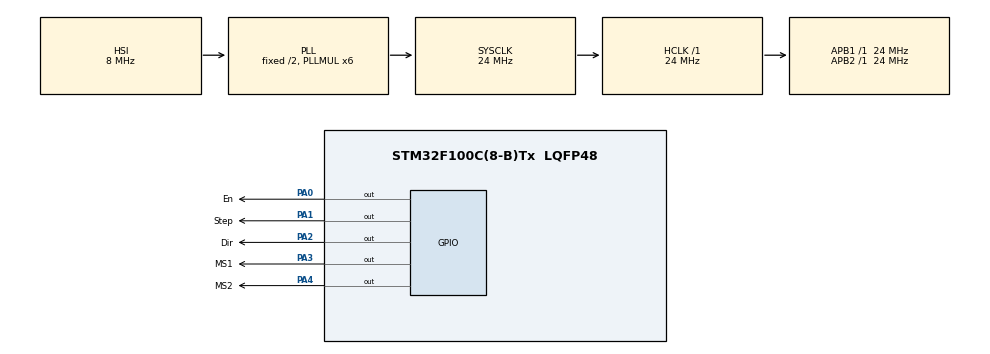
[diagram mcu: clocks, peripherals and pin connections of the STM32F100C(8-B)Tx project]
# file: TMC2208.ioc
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Mcu.Family=STM32F1
PD1-OSC_OUT.Mode=HSE-External-Oscillator
PD0-OSC_IN.Signal=RCC_OSC_IN
RCC.SYSCLKSource=RCC_SYSCLKSOURCE_PLLCLK
ProjectManager.StackSize=0x400
PA0-WKUP.GPIO_Label=En
PA0-WKUP.Signal=GPIO_Output
TIM1.ClockDivision=TIM_CLOCKDIVISION_DIV2
PD1-OSC_OUT.Signal=RCC_OSC_OUT
PA13.Signal=SYS_JTMS-SWDIO
TIM1.AutoReloadPreload=TIM_AUTORELOAD_PRELOAD_ENABLE
TIM1.Prescaler=100
ProjectManager.TargetToolchain=STM32CubeIDE
RCC.HCLKFreq_Value=24000000
RCC.APB2TimFreq_Value=24000000
PA1.Signal=GPIO_Output
RCC.AHBFreq_Value=24000000
PD0-OSC_IN.Mode=HSE-External-Oscillator
board=custom
RCC.PLLMUL=RCC_PLL_MUL6
PA0-WKUP.PinState=GPIO_PIN_SET
RCC.APB2Freq_Value=24000000
PA14.Mode=Serial_Wire
PA1.GPIO_Label=Step
PA13.Mode=Serial_Wire
Mcu.Name=STM32F100C(8-B)Tx
VP_TIM1_VS_ClockSourceINT.Mode=Internal
PA2.Signal=GPIO_Output
PA4.Signal=GPIO_Output
RCC.SYSCLKFreq_VALUE=24000000
Mcu.Package=LQFP48
PA2.GPIO_Label=Dir
PA14.Signal=SYS_JTCK-SWCLK
ProjectManager.HeapSize=0x200
NVIC.TIM1_UP_TIM16_IRQn=true\:0\:0\:false\:false\:true\:true\:true
NVIC.PriorityGroup=NVIC_PRIORITYGROUP_4
RCC.APB1TimFreq_Value=24000000
TIM1.Period=1
RCC.APB1Freq_Value=24000000
PA4.GPIO_Label=MS2
PA3.GPIO_Label=MS1
PA3.Signal=GPIO_Output

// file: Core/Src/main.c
/* USER CODE BEGIN Header */
/**
 ******************************************************************************
 * @file           : main.c
 * @brief          : Main program body
 ******************************************************************************
 * @attention
 *
 * <h2><center>&copy; Copyright (c) 2021 STMicroelectronics.
 * All rights reserved.</center></h2>
 *
 * This software component is licensed by ST under BSD 3-Clause license,
 * the "License"; You may not use this file except in compliance with the
 * License. You may obtain a copy of the License at:
 *                        opensource.org/licenses/BSD-3-Clause
 *
 ******************************************************************************
 */
/* USER CODE END Header */
#include "main.h"

/* USER CODE BEGIN Includes */
#include "tmc2208.h"
/* USER CODE END Includes */

TIM_HandleTypeDef htim1;

void SystemClock_Config(void);
static void MX_GPIO_Init(void);
static void MX_TIM1_Init(void);

int main(void)
{

  /* MCU Configuration--------------------------------------------------------*/

  /* Reset of all peripherals, Initializes the Flash interface and the Systick. */
  HAL_Init();

  /* Configure the system clock */
  SystemClock_Config();

  /* Initialize all configured peripherals */
  MX_GPIO_Init();
  MX_TIM1_Init();
  /* USER CODE BEGIN 2 */

	HAL_TIM_Base_Start_IT(&htim1);
    delayInit();

	motorSetDiv(STEP_DIV_BY_16);
	motorSetFreq(100);

	motorRun(2000, 1, 200);

  /* USER CODE END 2 */

  /* Infinite loop */
	while (1) {

	}
}

void SystemClock_Config(void)
{
  RCC_OscInitTypeDef RCC_OscInitStruct = {0};
  RCC_ClkInitTypeDef RCC_ClkInitStruct = {0};

  /** Initializes the RCC Oscillators according to the specified parameters
  * in the RCC_OscInitTypeDef structure.
  */
  RCC_OscInitStruct.OscillatorType = RCC_OSCILLATORTYPE_HSI;
  RCC_OscInitStruct.HSIState = RCC_HSI_ON;
  RCC_OscInitStruct.HSICalibrationValue = RCC_HSICALIBRATION_DEFAULT;
  RCC_OscInitStruct.PLL.PLLState = RCC_PLL_ON;
  RCC_OscInitStruct.PLL.PLLSource = RCC_PLLSOURCE_HSI_DIV2;
  RCC_OscInitStruct.PLL.PLLMUL = RCC_PLL_MUL6;
  if (HAL_RCC_OscConfig(&RCC_OscInitStruct) != HAL_OK)
  {
    Error_Handler();
  }
  /** Initializes the CPU, AHB and APB buses clocks
  */
  RCC_ClkInitStruct.ClockType = RCC_CLOCKTYPE_HCLK|RCC_CLOCKTYPE_SYSCLK
                              |RCC_CLOCKTYPE_PCLK1|RCC_CLOCKTYPE_PCLK2;
  RCC_ClkInitStruct.SYSCLKSource = RCC_SYSCLKSOURCE_PLLCLK;
  RCC_ClkInitStruct.AHBCLKDivider = RCC_SYSCLK_DIV1;
  RCC_ClkInitStruct.APB1CLKDivider = RCC_HCLK_DIV1;
  RCC_ClkInitStruct.APB2CLKDivider = RCC_HCLK_DIV1;

  if (HAL_RCC_ClockConfig(&RCC_ClkInitStruct, FLASH_LATENCY_0) != HAL_OK)
  {
    Error_Handler();
  }
}

static void MX_TIM1_Init(void)
{

  TIM_ClockConfigTypeDef sClockSourceConfig = {0};
  TIM_MasterConfigTypeDef sMasterConfig = {0};

  htim1.Instance = TIM1;
  htim1.Init.Prescaler = 100;
  htim1.Init.CounterMode = TIM_COUNTERMODE_UP;
  htim1.Init.Period = 1;
  htim1.Init.ClockDivision = TIM_CLOCKDIVISION_DIV2;
  htim1.Init.RepetitionCounter = 0;
  htim1.Init.AutoReloadPreload = TIM_AUTORELOAD_PRELOAD_ENABLE;
  if (HAL_TIM_Base_Init(&htim1) != HAL_OK)
  {
    Error_Handler();
  }
  sClockSourceConfig.ClockSource = TIM_CLOCKSOURCE_INTERNAL;
  if (HAL_TIM_ConfigClockSource(&htim1, &sClockSourceConfig) != HAL_OK)
  {
    Error_Handler();
  }
  sMasterConfig.MasterOutputTrigger = TIM_TRGO_RESET;
  sMasterConfig.MasterSlaveMode = TIM_MASTERSLAVEMODE_DISABLE;
  if (HAL_TIMEx_MasterConfigSynchronization(&htim1, &sMasterConfig) != HAL_OK)
  {
    Error_Handler();
  }

}

static void MX_GPIO_Init(void)
{
  GPIO_InitTypeDef GPIO_InitStruct = {0};

  /* GPIO Ports Clock Enable */
  __HAL_RCC_GPIOD_CLK_ENABLE();
  __HAL_RCC_GPIOA_CLK_ENABLE();

  /*Configure GPIO pin Output Level */
  HAL_GPIO_WritePin(En_GPIO_Port, En_Pin, GPIO_PIN_SET);

  /*Configure GPIO pin Output Level */
  HAL_GPIO_WritePin(GPIOA, Step_Pin|Dir_Pin|MS1_Pin|MS2_Pin, GPIO_PIN_RESET);

  /*Configure GPIO pins : En_Pin Step_Pin Dir_Pin MS1_Pin
                           MS2_Pin */
  GPIO_InitStruct.Pin = En_Pin|Step_Pin|Dir_Pin|MS1_Pin
                          |MS2_Pin;
  GPIO_InitStruct.Mode = GPIO_MODE_OUTPUT_PP;
  GPIO_InitStruct.Pull = GPIO_NOPULL;
  GPIO_InitStruct.Speed = GPIO_SPEED_FREQ_LOW;
  HAL_GPIO_Init(GPIOA, &GPIO_InitStruct);

}

void Error_Handler(void)
{
	__disable_irq();
	while (1) {
	}
}

/************************ (C) COPYRIGHT STMicroelectronics *****END OF FILE****/
